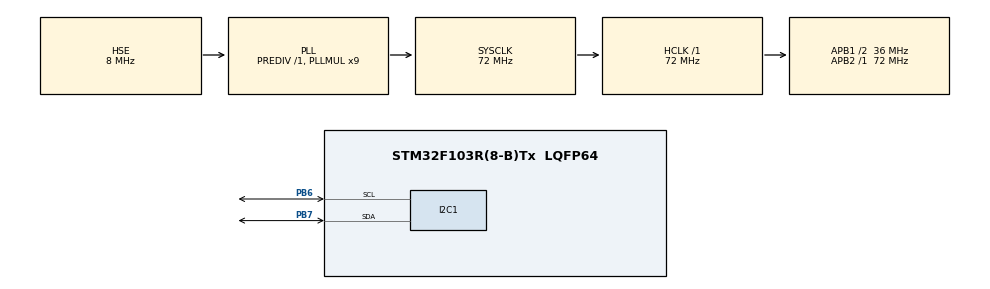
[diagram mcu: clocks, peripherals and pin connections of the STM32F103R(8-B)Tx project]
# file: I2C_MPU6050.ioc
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Mcu.Family=STM32F1
Mcu.Name=STM32F103R(8-B)Tx
Mcu.Package=LQFP64
NVIC.PriorityGroup=NVIC_PRIORITYGROUP_4
PA13.Mode=Serial_Wire
PA13.Signal=SYS_JTMS-SWDIO
PA14.Mode=Serial_Wire
PA14.Signal=SYS_JTCK-SWCLK
PB6.Mode=I2C
PB6.Signal=I2C1_SCL
PB7.Mode=I2C
PB7.Signal=I2C1_SDA
PD0-OSC_IN.Mode=HSE-External-Oscillator
PD0-OSC_IN.Signal=RCC_OSC_IN
PD1-OSC_OUT.Mode=HSE-External-Oscillator
PD1-OSC_OUT.Signal=RCC_OSC_OUT
ProjectManager.HeapSize=0x200
ProjectManager.StackSize=0x400
ProjectManager.TargetToolchain=STM32CubeIDE
RCC.AHBFreq_Value=72000000
RCC.APB1CLKDivider=RCC_HCLK_DIV2
RCC.APB1Freq_Value=36000000
RCC.APB1TimFreq_Value=72000000
RCC.APB2Freq_Value=72000000
RCC.APB2TimFreq_Value=72000000
RCC.HCLKFreq_Value=72000000
RCC.PLLMUL=RCC_PLL_MUL9
RCC.PLLSourceVirtual=RCC_PLLSOURCE_HSE
RCC.SYSCLKFreq_VALUE=72000000
RCC.SYSCLKSource=RCC_SYSCLKSOURCE_PLLCLK
RCC.USBFreq_Value=72000000
board=custom

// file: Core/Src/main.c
/* USER CODE BEGIN Header */
/**
  ******************************************************************************
  * @file           : main.c
  * @brief          : Main program body
  ******************************************************************************
  * @attention
  *
  * Copyright (c) 2026 STMicroelectronics.
  * All rights reserved.
  *
  * This software is licensed under terms that can be found in the LICENSE file
  * in the root directory of this software component.
  * If no LICENSE file comes with this software, it is provided AS-IS.
  *
  ******************************************************************************
  */
/* USER CODE END Header */
#include "main.h"
#include "i2c-lcd.h"
#include "stdio.h"

/* USER CODE BEGIN Includes */
#define MPU6050_ADDR (0x68<<1)
#define PWR_MGMT_1 0x6B
#define ACCL_START 0x3B
/* USER CODE END Includes */

/* USER CODE BEGIN PTD */
volatile uint8_t raw_data[14];
volatile int found;
/* USER CODE END PTD */

I2C_HandleTypeDef hi2c1;

/* USER CODE BEGIN PV */
int16_t ax, ay, az;
int16_t gx, gy, gz;
int16_t temp_raw;
char buf[16];

float accel_x, accel_y, accel_z;
float gyro_x, gyro_y, gyro_z;
float temperature;
/* USER CODE END PV */

void SystemClock_Config(void);
static void MX_GPIO_Init(void);
static void MX_I2C1_Init(void);
/* USER CODE BEGIN PFP */
volatile HAL_StatusTypeDef readStatus;
/* USER CODE END PFP */

/* USER CODE BEGIN 0 */
	void wake_up_mpu(void){
		uint8_t wake = 0x00;
		HAL_I2C_Mem_Write(&hi2c1,MPU6050_ADDR,PWR_MGMT_1,1,&wake,1,100);
}

	void read_raw_data(void){
		readStatus = HAL_I2C_Mem_Read(&hi2c1, MPU6050_ADDR,ACCL_START,1,raw_data,14,100);
	}

/* USER CODE END 0 */

int main(void)
{

  /* MCU Configuration--------------------------------------------------------*/

  /* Reset of all peripherals, Initializes the Flash interface and the Systick. */
  HAL_Init();

  /* Configure the system clock */
  SystemClock_Config();

  /* Initialize all configured peripherals */
  MX_GPIO_Init();
  MX_I2C1_Init();

  /* USER CODE BEGIN 2 */
  lcd_init();
  wake_up_mpu();
  HAL_StatusTypeDef status;
  status = HAL_I2C_IsDeviceReady(&hi2c1, MPU6050_ADDR, 3, 100);

  if (status == HAL_OK) {
      // MPU found — put breakpoint here
       found = 1;
  } else {
      // MPU NOT found — put breakpoint here
       found = 0;
  }
  /* USER CODE END 2 */

  /* Infinite loop */
  while (1)
  {

    /* USER CODE BEGIN 3 */

	  read_raw_data();

	  ax = (raw_data[0] << 8) | raw_data[1];
	      ay = (raw_data[2] << 8) | raw_data[3];
	      az = (raw_data[4] << 8) | raw_data[5];

	      temp_raw = (raw_data[6] << 8) | raw_data[7];

	      gx = (raw_data[8] << 8) | raw_data[9];
	      gy = (raw_data[10] << 8) | raw_data[11];
	      gz = (raw_data[12] << 8) | raw_data[13];

	      accel_x = ax / 16384.0f;
	      accel_y = ay / 16384.0f;
	      accel_z = az / 16384.0f;

	      gyro_x = gx / 131.0f;
	      gyro_y = gy / 131.0f;
	      gyro_z = gz / 131.0f;

	      temperature = (temp_raw / 340.0f) + 36.53f;

	      lcd_put_cur(0, 0);
	      lcd_send_string("AX:");
	      sprintf(buf, "%.2f", accel_x);
	      lcd_send_string(buf);

	      HAL_Delay(10);

  }
  /* USER CODE END 3 */
}

void SystemClock_Config(void)
{
  RCC_OscInitTypeDef RCC_OscInitStruct = {0};
  RCC_ClkInitTypeDef RCC_ClkInitStruct = {0};

  /** Initializes the RCC Oscillators according to the specified parameters
  * in the RCC_OscInitTypeDef structure.
  */
  RCC_OscInitStruct.OscillatorType = RCC_OSCILLATORTYPE_HSE;
  RCC_OscInitStruct.HSEState = RCC_HSE_ON;
  RCC_OscInitStruct.HSEPredivValue = RCC_HSE_PREDIV_DIV1;
  RCC_OscInitStruct.HSIState = RCC_HSI_ON;
  RCC_OscInitStruct.PLL.PLLState = RCC_PLL_ON;
  RCC_OscInitStruct.PLL.PLLSource = RCC_PLLSOURCE_HSE;
  RCC_OscInitStruct.PLL.PLLMUL = RCC_PLL_MUL9;
  if (HAL_RCC_OscConfig(&RCC_OscInitStruct) != HAL_OK)
  {
    Error_Handler();
  }

  /** Initializes the CPU, AHB and APB buses clocks
  */
  RCC_ClkInitStruct.ClockType = RCC_CLOCKTYPE_HCLK|RCC_CLOCKTYPE_SYSCLK
                              |RCC_CLOCKTYPE_PCLK1|RCC_CLOCKTYPE_PCLK2;
  RCC_ClkInitStruct.SYSCLKSource = RCC_SYSCLKSOURCE_PLLCLK;
  RCC_ClkInitStruct.AHBCLKDivider = RCC_SYSCLK_DIV1;
  RCC_ClkInitStruct.APB1CLKDivider = RCC_HCLK_DIV2;
  RCC_ClkInitStruct.APB2CLKDivider = RCC_HCLK_DIV1;

  if (HAL_RCC_ClockConfig(&RCC_ClkInitStruct, FLASH_LATENCY_2) != HAL_OK)
  {
    Error_Handler();
  }
}

static void MX_I2C1_Init(void)
{

  hi2c1.Instance = I2C1;
  hi2c1.Init.ClockSpeed = 100000;
  hi2c1.Init.DutyCycle = I2C_DUTYCYCLE_2;
  hi2c1.Init.OwnAddress1 = 0;
  hi2c1.Init.AddressingMode = I2C_ADDRESSINGMODE_7BIT;
  hi2c1.Init.DualAddressMode = I2C_DUALADDRESS_DISABLE;
  hi2c1.Init.OwnAddress2 = 0;
  hi2c1.Init.GeneralCallMode = I2C_GENERALCALL_DISABLE;
  hi2c1.Init.NoStretchMode = I2C_NOSTRETCH_DISABLE;
  if (HAL_I2C_Init(&hi2c1) != HAL_OK)
  {
    Error_Handler();
  }

}

static void MX_GPIO_Init(void)
{

  /* GPIO Ports Clock Enable */
  __HAL_RCC_GPIOD_CLK_ENABLE();
  __HAL_RCC_GPIOA_CLK_ENABLE();
  __HAL_RCC_GPIOB_CLK_ENABLE();

}

void Error_Handler(void)
{
  __disable_irq();
  while (1)
  {
  }
}
